# nrf7140_secure register map
Vendor: Nordic Semiconductor; Series: nRF71; File version: 1
CPU: CM33 r0p4, little endian, MPU, no FPU, 3 interrupt priority bits, 480 interrupts, 8 SAU regions
Registers are 32-bit, read-write, reset 0x0 unless marked. A register's access mark holds for its fields unless they carry their own. Offsets are from the block's base; [hi:lo] are bit positions; lines under a group give offsets from that group; {n}, {i} and the like mark numbered series; 'fields as' and 'values as' point back to an identical list.

## SPU000_S — System protection unit 0
Base 0x51000000
Same registers: SPU010_S 0x51010000, SPU310_S 0x59010000, SPU410_S 0x5A010000, SPU110_S 0x5F080000, SPU111_S 0x5F090000, SPU120_S 0x5F8C0000, SPU121_S 0x5F8D0000, SPU122_S 0x5F8E0000, SPU130_S 0x5F900000, SPU131_S 0x5F920000, SPU132_S 0x5F980000, SPU133_S 0x5F990000, SPU134_S 0x5F9A0000, SPU135_S 0x5F9B0000, SPU136_S 0x5F9C0000, SPU137_S 0x5F9D0000, SPU200_NS 0xBF000000, SPU210_NS 0xBF010000
0x100 EVENTS_PERIPHACCERR — A security violation has been detected on one or several peripherals
  [0] EVENTS_PERIPHACCERR
    0=NotGenerated (Event not generated); 1=Generated (Event generated)
0x300 INTEN — Enable or disable interrupt
  [0] PERIPHACCERR — Enable or disable interrupt for event PERIPHACCERR
    0=Disabled; 1=Enabled
0x304 INTENSET — Enable interrupt
  [0] PERIPHACCERR — Write '1' to enable interrupt for event PERIPHACCERR
    on read: 0=Disabled (Read: Disabled); 1=Enabled (Read: Enabled) | on write: 1=Set (Enable)
0x308 INTENCLR — Disable interrupt
  [0] PERIPHACCERR — Write '1' to disable interrupt for event PERIPHACCERR
    on read: 0=Disabled (Read: Disabled); 1=Enabled (Read: Enabled) | on write: 1=Clear (Disable)
0x30C INTPEND ro — Pending interrupts
  [0] PERIPHACCERR — Read pending status of interrupt for event PERIPHACCERR
    on read: 0=NotPending (Read: Not pending); 1=Pending (Read: Pending)
0x404 PERIPHACCERR group — Unspecified
  0x00 ADDRESS ro — Address of the transaction that caused first error.
    [15:0] ADDRESS
  0x04 INFO ro — Information about the transaction that caused first error.
    [3:0] OWNERID
{0x500+4i} PERIPH[{i}] (i=0..31) group — Unspecified
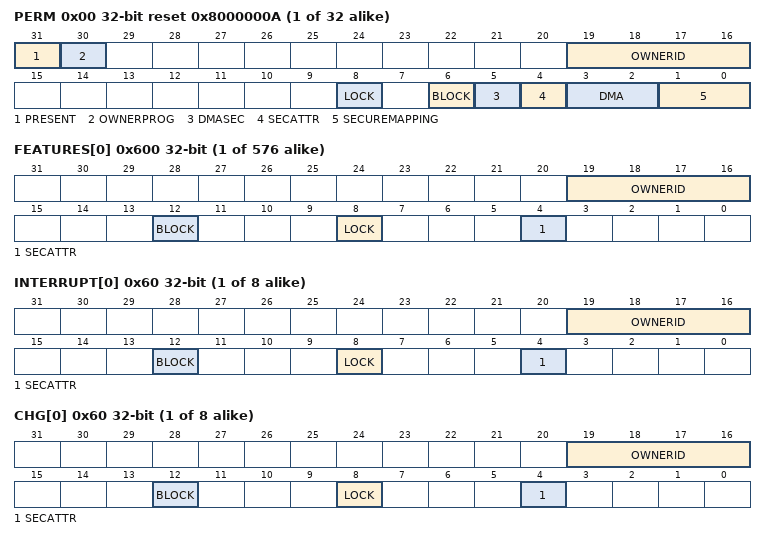
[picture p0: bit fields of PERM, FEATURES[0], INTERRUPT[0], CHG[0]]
  0x00 PERM reset 0x8000000A — Description cluster: Get and set the applicable access permissions for the peripheral slave index n
    [31] PRESENT ro — Indicates if a peripheral is present with peripheral slave index n
      0=NotPresent (Peripheral is not present); 1=IsPresent (Peripheral is present)
    [30] OWNERPROG ro — Indicates if OWNERID is programmable or not
      0=NotProgrammable (OWNERID is not programmable); 1=Programmable (OWNERID is programmable)
    [19:16] OWNERID — Peripheral owner ID
    [8] LOCK write-1-sets
      0=Unlocked (This register can be updated); 1=Locked (The content of this register can not be changed until the next reset)
    [6] BLOCK write-1-sets — Peripheral block
      0=Available (Peripheral is accessible); 1=Blocked (Peripheral cannot be accessed until next reset)
    [5] DMASEC — Security attribution for the DMA transfer
      1=Secure (DMA transfers initiated by this peripheral have the secure attribute set); 0=NonSecure (DMA transfers initiated by this peripheral have the non-secure attribute set)
    [4] SECATTR — Peripheral security mapping
      1=Secure (Peripheral is mapped in secure peripheral address space); 0=NonSecure (If SECUREMAPPING == UserSelectable: Peripheral is mapped in non-secure peripheral address space. If SECUREMAPPING == Split: Peripheral is mapped in non-secure and secure peripheral address space.)
    [3:2] DMA ro — Read the peripheral DMA capabilities
      0=NoDMA (Peripheral has no DMA capability); 1=NoSeparateAttribute (Peripheral has DMA and DMA transfers always have the same security attribute as assigned to the peripheral); 2=SeparateAttribute (Peripheral has DMA and DMA transfers can have a different security attribute than the one assigned to the peripheral)
    [1:0] SECUREMAPPING ro — Read capabilities for TrustZone Cortex-M secure attribute
      0=NonSecure (This peripheral is always accessible as a non-secure peripheral); 1=Secure (This peripheral is always accessible as a secure peripheral); 2=UserSelectable (Non-secure or secure attribute for this peripheral is defined by the PERIPH[n].PERM register); 3=Split (This peripheral implements the split security mechanism.)
{0x600+4i} FEATURES[{i}] (i=0..575) — Description collection: Configuration of split security feature [n]
  [19:16] OWNERID — Feature owner ID
  [12] BLOCK write-1-sets — BLOCK feature
    0=Available (Feature is accessible); 1=Blocked (Feature cannot be accessed until next reset)
  [8] LOCK write-1-sets — LOCK feature
    0=Unlocked (Feature permissions can be updated); 1=Locked (Feature permissions can not be changed until the next reset)
  [4] SECATTR — SECATTR feature
    0=NonSecure (Feature is available for non-secure usage); 1=Secure (Feature is reserved for secure usage)
0x600 FEATURE group — Unspecified
  0x00 STRUCT0 group — Unspecified
    0x00 IPCT group — Unspecified
      {0x0+4l} CH[{l}] (l=0..23) — Description collection: Configuration of features for channel n of IPCT
        fields as FEATURES[0]
      {0x60+4l} INTERRUPT[{l}] (l=0..7) — Description collection: Configuration of features for interrupt n of IPCT
        fields as FEATURES[0]
    0x80 DPPIC group — Unspecified
      {0x0+4l} CH[{l}] (l=0..23) — Description collection: Configuration of features for channel n of DPPIC
        fields as FEATURES[0]
      {0x60+4l} CHG[{l}] (l=0..7) — Description collection: Configuration of features for channel group n of DPPIC
        fields as FEATURES[0]
    0x100 COEXC group — Unspecified
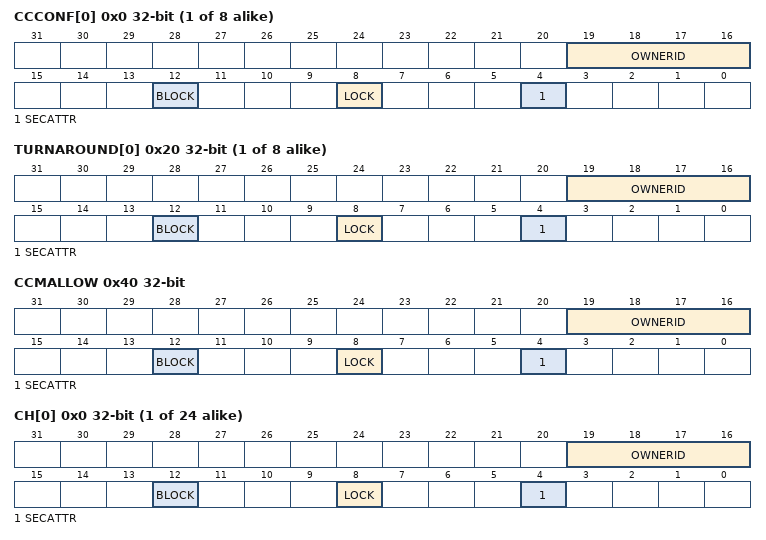
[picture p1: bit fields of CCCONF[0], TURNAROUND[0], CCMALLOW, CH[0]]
      {0x0+4l} CCCONF[{l}] (l=0..7) — Description collection: Configuration of features for CCCONF[n] of COEXC
        fields as FEATURES[0]
      {0x20+4l} TURNAROUND[{l}] (l=0..7) — Description collection: Configuration of features for TURNAROUND[n] of COEXC
        fields as FEATURES[0]
      0x40 CCMALLOW — Configuration of features for CCMALLOW of COEXC
        fields as FEATURES[0]
    {0x100+0x40*k} GPIOTE[{k}] (k=0..0) group (alternate view of COEXC) — Unspecified
      {0x0+4l} CH[{l}] (l=0..7) — Description collection: Configuration of features for channel o of GPIOTE[n]
        fields as FEATURES[0]
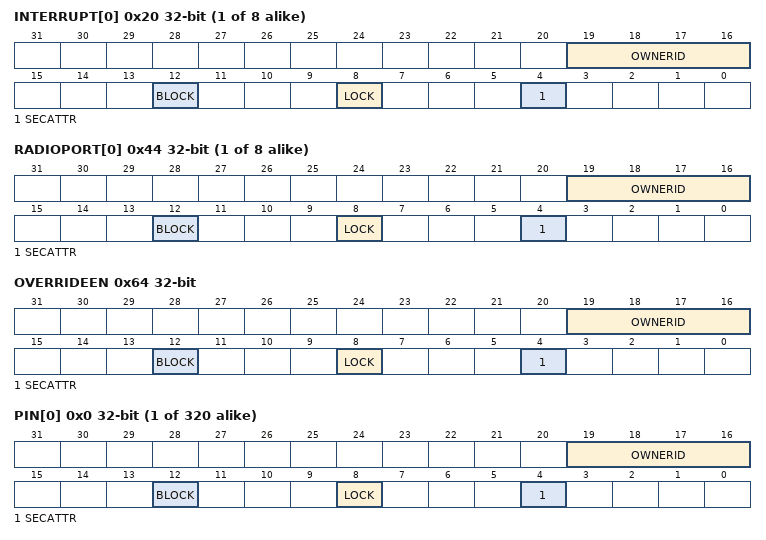
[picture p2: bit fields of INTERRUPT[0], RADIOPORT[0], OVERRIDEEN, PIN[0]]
      {0x20+4l} INTERRUPT[{l}] (l=0..7) — Description collection: Configuration of features for interrupt o of GPIOTE[n]
        fields as FEATURES[0]
    0x100 ANTSWC group (alternate view of COEXC) — Unspecified
      {0x44+4l} RADIOPORT[{l}] (l=0..7) — Description collection: Configuration of features for radio port [n] of ANTSWC
        fields as FEATURES[0]
      0x64 OVERRIDEEN — Configuration of features for OVERRIDE enable of ANTSWC
        fields as FEATURES[0]
    {0x200+0x80*k} GPIO[{k}] (k=0..9) group — Unspecified
      {0x0+4l} PIN[{l}] (l=0..31) — Description collection: Configuration of features for GPIO[n] PIN[o]
        fields as FEATURES[0]
    0x200 STRUCT0 group (alternate view of GPIO[*]) — Unspecified
      0x00 GRTC group — Unspecified
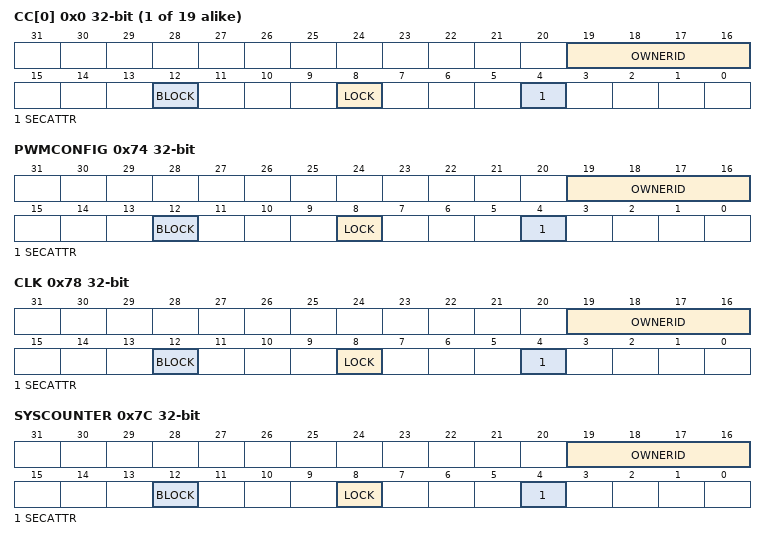
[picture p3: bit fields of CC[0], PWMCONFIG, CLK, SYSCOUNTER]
        {0x0+4m} CC[{m}] (m=0..18) — Description collection: Configuration of features for CC n of GRTC
          fields as FEATURES[0]
        0x74 PWMCONFIG — Configuration of feature for PWMCONFIG of GRTC
          fields as FEATURES[0]
        0x78 CLK — Configuration of features for CLKOUT/CLKCFG of GRTC
          fields as FEATURES[0]
        0x7C SYSCOUNTER — Configuration of features for SYSCOUNTERL/SYSCOUNTERH of GRTC
          fields as FEATURES[0]
        {0x80+4m} INTERRUPT[{m}] (m=0..14) — Description collection: Configuration of features for interrupt n of GRTC
          fields as FEATURES[0]
    {0x200+0xC*k} MRAMC[{k}] (k=0..1) group (alternate view of GPIO[{k}]) — Unspecified
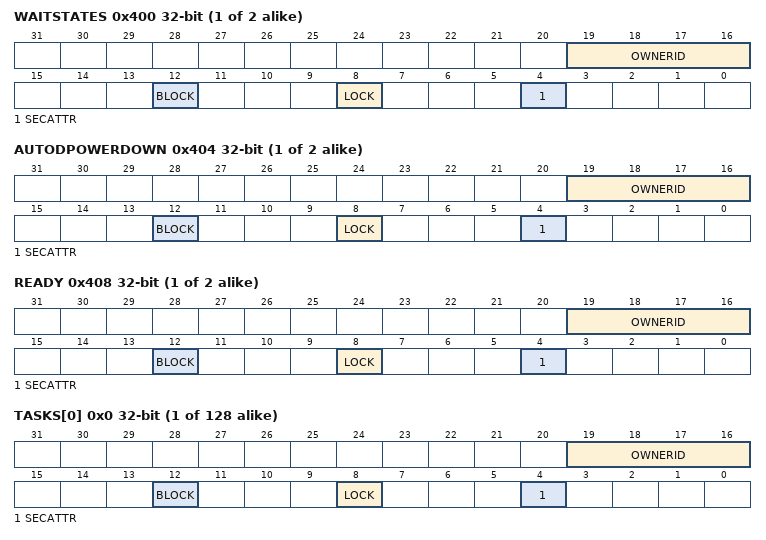
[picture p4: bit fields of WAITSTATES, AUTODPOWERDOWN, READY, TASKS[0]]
      0x400 WAITSTATES — Description cluster: Configuration of features for WAITSTATES of MRAMC [n]
        fields as FEATURES[0]
      0x404 AUTODPOWERDOWN — Description cluster: Configuration of features for POWER.AUTODPOWERDOWN of MRAMC [n]
        fields as FEATURES[0]
      0x408 READY — Description cluster: Configuration of features for READY and READYNEXT of MRAMC [n]
        fields as FEATURES[0]
  0x00 BELLS group (alternate view of STRUCT0) — Unspecified
    {0x0+0xC0*k} PROCESSOR[{k}] (k=0..7) group — Unspecified
      {0x0+4l} TASKS[{l}] (l=0..15) — Description collection: Configuration of features for tasks pair [(o * 2) + 1:o * 2] of Processor ID n
        fields as FEATURES[0]
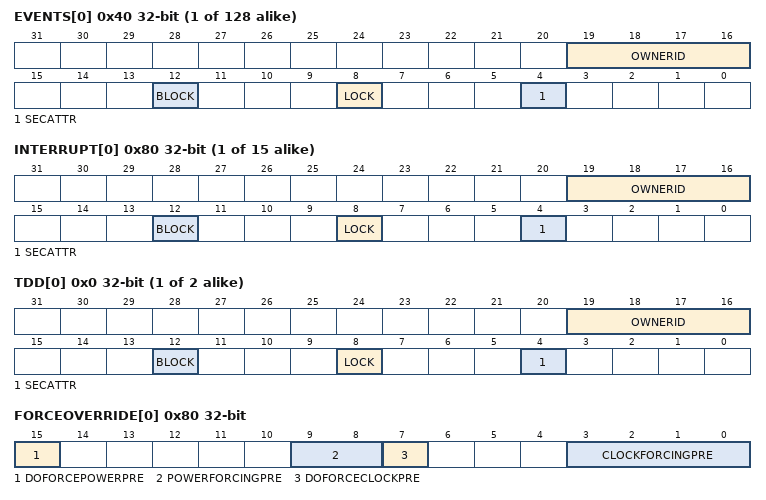
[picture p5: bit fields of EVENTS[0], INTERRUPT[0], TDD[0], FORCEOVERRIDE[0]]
      {0x40+4l} EVENTS[{l}] (l=0..15) — Description collection: Configuration of features for events pair [(o * 2) + 1:o * 2] of Processor ID n
        fields as FEATURES[0]
      {0x80+4l} INTERRUPT[{l}] (l=0..15) — Description collection: Configuration of features for interrupt register pair [(o * 2) + 1:o * 2] of Processor ID n
        fields as FEATURES[0]
  0x00 STRUCT1 group (alternate view of STRUCT0) — Unspecified
    {0x0+4k} TDD[{k}] (k=0..1) — Description collection: Configuration of features for functionality n of TDD
      fields as FEATURES[0]
0xF00 PCGCS group — Unspecified
  {0x0+4j} PENALTY[{j}] (j=0..0) reset 0xFFFFFFFC — Description collection: Penalty level for power/clock pair n. When FULL_PCP_ZERO feature is not supported, PENALTY[0] address overlaps the PENALTY0 address and register description for PENALTY[0] is not valid.
    [1:0] PENALTY — Penalty level
  {0x80+4j} FORCEOVERRIDE[{j}] (j=0..0) — Description collection: Force override of power/clock pair n.
    [15] DOFORCEPOWERPRE, [9:8] POWERFORCINGPRE, [7] DOFORCECLOCKPRE, [3:0] CLOCKFORCINGPRE
